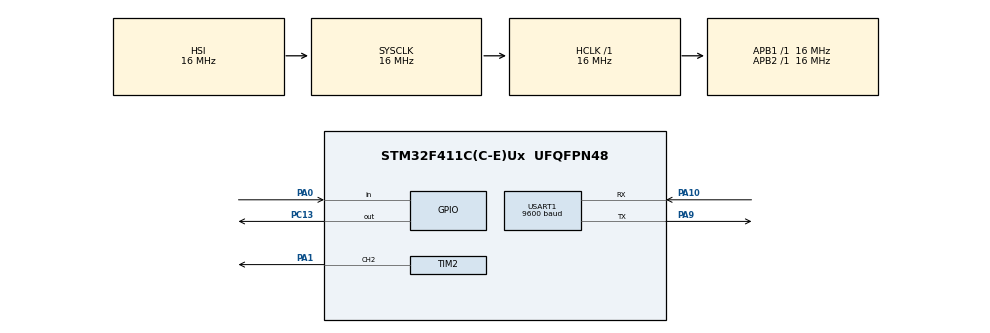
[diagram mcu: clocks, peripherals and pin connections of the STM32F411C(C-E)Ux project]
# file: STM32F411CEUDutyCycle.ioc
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Mcu.Family=STM32F4
Mcu.Name=STM32F411C(C-E)Ux
Mcu.Package=UFQFPN48
NVIC.PriorityGroup=NVIC_PRIORITYGROUP_4
PA0-WKUP.GPIO_PuPd=GPIO_PULLUP
PA0-WKUP.Signal=GPIO_Input
PA1.Signal=S_TIM2_CH2
PA10.Mode=Asynchronous
PA10.Signal=USART1_RX
PA9.Mode=Asynchronous
PA9.Signal=USART1_TX
PC13-ANTI_TAMP.Signal=GPIO_Output
ProjectManager.HeapSize=0x200
ProjectManager.StackSize=0x400
ProjectManager.TargetToolchain=STM32CubeIDE
RCC.AHBFreq_Value=16000000
RCC.APB1Freq_Value=16000000
RCC.APB2Freq_Value=16000000
RCC.CortexFreq_Value=16000000
RCC.HSE_VALUE=25000000
RCC.HSI_VALUE=16000000
RCC.LSE_VALUE=32768
RCC.SYSCLKFreq_VALUE=16000000
RCC.VCOOutputFreq_Value=192000000
SH.S_TIM2_CH2.0=TIM2_CH2,PWM Generation2 CH2
TIM2.Channel-PWM\ Generation2\ CH2=TIM_CHANNEL_2
TIM2.Period=99
TIM2.Prescaler=83
USART1.BaudRate=9600
USART1.VirtualMode=VM_ASYNC
board=custom

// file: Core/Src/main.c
/* USER CODE BEGIN Header */
/**
  ******************************************************************************
  * @file           : main.c
  * @brief          : Main program body
  ******************************************************************************
  * @attention
  *
  * Copyright (c) 2025 STMicroelectronics.
  * All rights reserved.
  *
  * This software is licensed under terms that can be found in the LICENSE file
  * in the root directory of this software component.
  * If no LICENSE file comes with this software, it is provided AS-IS.
  *
  ******************************************************************************
  */
/* USER CODE END Header */
#include "main.h"
#include <string.h>
#include <stdio.h>

TIM_HandleTypeDef htim2;

UART_HandleTypeDef huart1;

void SystemClock_Config(void);
static void MX_GPIO_Init(void);
static void MX_TIM2_Init(void);
static void MX_USART1_UART_Init(void);
void set_pwm_duty(uint16_t duty);
void send_duty_cycle(uint16_t duty);

int main(void)
{

  /* MCU Configuration--------------------------------------------------------*/

  /* Reset of all peripherals, Initializes the Flash interface and the Systick. */
  HAL_Init();

  /* Configure the system clock */
  SystemClock_Config();

  /* Initialize all configured peripherals */
  MX_GPIO_Init();
  MX_TIM2_Init();
  MX_USART1_UART_Init();
  /* USER CODE BEGIN 2 */
  HAL_TIM_PWM_Start(&htim2, TIM_CHANNEL_2);
  /* USER CODE END 2 */

  /* Infinite loop */
  /* USER CODE BEGIN WHILE */
  while (1)
  {
	   // Read button state (active low)

	    GPIO_PinState buttonState = HAL_GPIO_ReadPin(GPIOA, GPIO_PIN_0);

	    uint16_t duty = (buttonState == GPIO_PIN_RESET) ? 1000 : 0;

	    set_pwm_duty(duty);

	    send_duty_cycle(duty);

	    HAL_Delay(100); // Update every 100ms
	  //HAL_GPIO_WritePin(GPIOC,GPIO_PIN_13,GPIO_PIN_SET);
	  //HAL_Delay(1000);
	  //HAL_GPIO_WritePin(GPIOC,GPIO_PIN_13,GPIO_PIN_RESET);
	  //HAL_Delay(1000);
    /* USER CODE END WHILE */

  }
}

// Set PWM duty cycle (0–1000)
void set_pwm_duty(uint16_t duty)
{
  __HAL_TIM_SET_COMPARE(&htim2, TIM_CHANNEL_2, duty);
}

//  Send duty cycle over UART
void send_duty_cycle(uint16_t duty)
{
  char msg[32];
  sprintf(msg, "Duty Cycle: %d\r\n", duty * 100 / 1000);
  HAL_UART_Transmit(&huart1, (uint8_t*)msg, strlen(msg), HAL_MAX_DELAY);
}
void SystemClock_Config(void)
{
  RCC_OscInitTypeDef RCC_OscInitStruct = {0};
  RCC_ClkInitTypeDef RCC_ClkInitStruct = {0};

  /** Configure the main internal regulator output voltage
  */
  __HAL_RCC_PWR_CLK_ENABLE();
  __HAL_PWR_VOLTAGESCALING_CONFIG(PWR_REGULATOR_VOLTAGE_SCALE1);

  /** Initializes the RCC Oscillators according to the specified parameters
  * in the RCC_OscInitTypeDef structure.
  */
  RCC_OscInitStruct.OscillatorType = RCC_OSCILLATORTYPE_HSI;
  RCC_OscInitStruct.HSIState = RCC_HSI_ON;
  RCC_OscInitStruct.HSICalibrationValue = RCC_HSICALIBRATION_DEFAULT;
  RCC_OscInitStruct.PLL.PLLState = RCC_PLL_NONE;
  if (HAL_RCC_OscConfig(&RCC_OscInitStruct) != HAL_OK)
  {
    Error_Handler();
  }

  /** Initializes the CPU, AHB and APB buses clocks
  */
  RCC_ClkInitStruct.ClockType = RCC_CLOCKTYPE_HCLK|RCC_CLOCKTYPE_SYSCLK
                              |RCC_CLOCKTYPE_PCLK1|RCC_CLOCKTYPE_PCLK2;
  RCC_ClkInitStruct.SYSCLKSource = RCC_SYSCLKSOURCE_HSI;
  RCC_ClkInitStruct.AHBCLKDivider = RCC_SYSCLK_DIV1;
  RCC_ClkInitStruct.APB1CLKDivider = RCC_HCLK_DIV1;
  RCC_ClkInitStruct.APB2CLKDivider = RCC_HCLK_DIV1;

  if (HAL_RCC_ClockConfig(&RCC_ClkInitStruct, FLASH_LATENCY_0) != HAL_OK)
  {
    Error_Handler();
  }
}

static void MX_TIM2_Init(void)
{

  TIM_MasterConfigTypeDef sMasterConfig = {0};
  TIM_OC_InitTypeDef sConfigOC = {0};

  htim2.Instance = TIM2;
  htim2.Init.Prescaler = 83;
  htim2.Init.CounterMode = TIM_COUNTERMODE_UP;
  htim2.Init.Period = 99;
  htim2.Init.ClockDivision = TIM_CLOCKDIVISION_DIV1;
  htim2.Init.AutoReloadPreload = TIM_AUTORELOAD_PRELOAD_DISABLE;
  if (HAL_TIM_PWM_Init(&htim2) != HAL_OK)
  {
    Error_Handler();
  }
  sMasterConfig.MasterOutputTrigger = TIM_TRGO_RESET;
  sMasterConfig.MasterSlaveMode = TIM_MASTERSLAVEMODE_DISABLE;
  if (HAL_TIMEx_MasterConfigSynchronization(&htim2, &sMasterConfig) != HAL_OK)
  {
    Error_Handler();
  }
  sConfigOC.OCMode = TIM_OCMODE_PWM1;
  sConfigOC.Pulse = 0;
  sConfigOC.OCPolarity = TIM_OCPOLARITY_HIGH;
  sConfigOC.OCFastMode = TIM_OCFAST_DISABLE;
  if (HAL_TIM_PWM_ConfigChannel(&htim2, &sConfigOC, TIM_CHANNEL_2) != HAL_OK)
  {
    Error_Handler();
  }
  HAL_TIM_MspPostInit(&htim2);

}

static void MX_USART1_UART_Init(void)
{

  huart1.Instance = USART1;
  huart1.Init.BaudRate = 9600;
  huart1.Init.WordLength = UART_WORDLENGTH_8B;
  huart1.Init.StopBits = UART_STOPBITS_1;
  huart1.Init.Parity = UART_PARITY_NONE;
  huart1.Init.Mode = UART_MODE_TX_RX;
  huart1.Init.HwFlowCtl = UART_HWCONTROL_NONE;
  huart1.Init.OverSampling = UART_OVERSAMPLING_16;
  if (HAL_UART_Init(&huart1) != HAL_OK)
  {
    Error_Handler();
  }

}

static void MX_GPIO_Init(void)
{
  GPIO_InitTypeDef GPIO_InitStruct = {0};

  /* GPIO Ports Clock Enable */
  __HAL_RCC_GPIOC_CLK_ENABLE();
  __HAL_RCC_GPIOA_CLK_ENABLE();

  /*Configure GPIO pin Output Level */
  HAL_GPIO_WritePin(GPIOC, GPIO_PIN_13, GPIO_PIN_RESET);

  /*Configure GPIO pin : PC13 */
  GPIO_InitStruct.Pin = GPIO_PIN_13;
  GPIO_InitStruct.Mode = GPIO_MODE_OUTPUT_PP;
  GPIO_InitStruct.Pull = GPIO_NOPULL;
  GPIO_InitStruct.Speed = GPIO_SPEED_FREQ_LOW;
  HAL_GPIO_Init(GPIOC, &GPIO_InitStruct);

  /*Configure GPIO pin : PA0 */
  GPIO_InitStruct.Pin = GPIO_PIN_0;
  GPIO_InitStruct.Mode = GPIO_MODE_INPUT;
  GPIO_InitStruct.Pull = GPIO_PULLUP;
  HAL_GPIO_Init(GPIOA, &GPIO_InitStruct);

}

void Error_Handler(void)
{
  __disable_irq();
  while (1)
  {
  }
}
